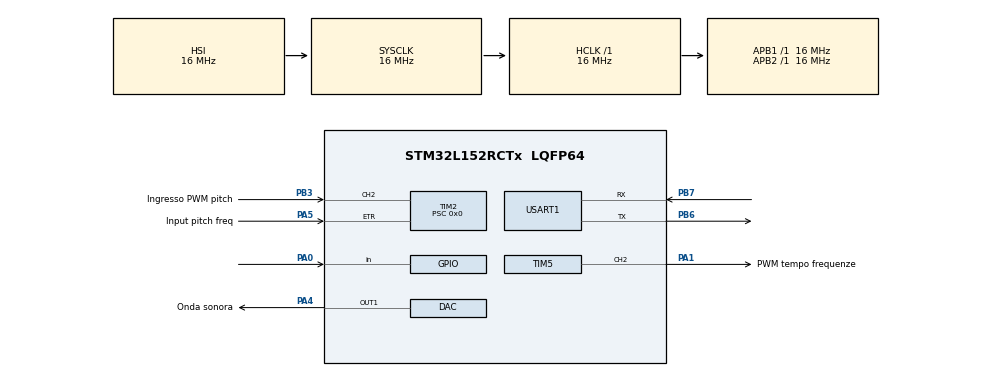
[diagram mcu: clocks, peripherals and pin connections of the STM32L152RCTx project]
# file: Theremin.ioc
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DAC.DAC_Trigger=DAC_TRIGGER_T6_TRGO
Dma.DAC_CH1.0.Direction=DMA_MEMORY_TO_PERIPH
Dma.DAC_CH1.0.Instance=DMA1_Channel2
Dma.DAC_CH1.0.MemDataAlignment=DMA_MDATAALIGN_HALFWORD
Dma.DAC_CH1.0.MemInc=DMA_MINC_ENABLE
Dma.DAC_CH1.0.Mode=DMA_CIRCULAR
Dma.DAC_CH1.0.PeriphDataAlignment=DMA_PDATAALIGN_HALFWORD
Dma.DAC_CH1.0.PeriphInc=DMA_PINC_DISABLE
Dma.DAC_CH1.0.Priority=DMA_PRIORITY_HIGH
Dma.Request0=DAC_CH1
Mcu.Family=STM32L1
Mcu.Name=STM32L152RCTx
Mcu.Package=LQFP64
NVIC.DMA1_Channel2_IRQn=true\:0\:0\:false\:false\:true\:false\:true
NVIC.PriorityGroup=NVIC_PRIORITYGROUP_4
NVIC.TIM2_IRQn=true\:0\:0\:false\:false\:true\:true\:true
NVIC.TIM5_IRQn=true\:0\:0\:false\:false\:true\:true\:true
PA0-WKUP1.Signal=GPIO_Input
PA1.GPIO_Label=PWM tempo frequenze
PA1.Signal=S_TIM5_CH2
PA4.GPIO_Label=Onda sonora
PA4.Signal=COMP_DAC1_group
PA5.GPIO_Label=Input pitch freq
PA5.GPIO_PuPd=GPIO_PULLDOWN
PA5.GPIO_Speed=GPIO_SPEED_FREQ_LOW
PA5.Signal=S_TIM2_CH1_ETR
PB3.GPIO_Label=Ingresso PWM pitch
PB3.Signal=S_TIM2_CH2
PB6.Mode=Asynchronous
PB6.Signal=USART1_TX
PB7.Mode=Asynchronous
PB7.Signal=USART1_RX
ProjectManager.HeapSize=0x200
ProjectManager.StackSize=0x400
ProjectManager.TargetToolchain=STM32CubeIDE
RCC.48MHZClocksFreq_Value=24000000
RCC.AHBFreq_Value=16000000
RCC.APB1Freq_Value=16000000
RCC.APB1TimFreq_Value=16000000
RCC.APB2Freq_Value=16000000
RCC.APB2TimFreq_Value=16000000
RCC.HCLKFreq_Value=16000000
RCC.HSE_VALUE=24000000
RCC.HSI_VALUE=16000000
RCC.LSE_VALUE=32768
RCC.MSI_VALUE=2097000
RCC.SYSCLKFreq_VALUE=16000000
RCC.SYSCLKSource=RCC_SYSCLKSOURCE_HSI
RCC.VCOOutputFreq_Value=48000000
SH.COMP_DAC1_group.0=DAC_OUT1,DAC_OUT1
SH.S_TIM2_CH1_ETR.0=TIM2_ETR,ClockSourceETR_Mode2
SH.S_TIM2_CH2.0=TIM2_CH2,TriggerSource_TI2FP2
SH.S_TIM2_CH2.1=TIM2_CH2,Input_Capture2_from_TI2
SH.S_TIM5_CH2.0=TIM5_CH2,PWM Generation2 CH2
TIM2.Channel-Input_Capture2_from_TI2=TIM_CHANNEL_2
TIM2.Prescaler=0x0
TIM3.Channel-PWM\ Generation2\ No\ Output=TIM_CHANNEL_2
TIM5.AutoReloadPreload=TIM_AUTORELOAD_PRELOAD_ENABLE
TIM5.Channel-PWM\ Generation2\ CH2=TIM_CHANNEL_2
TIM5.Period=160000
TIM5.Pulse-PWM\ Generation2\ CH2=0x1f40
TIM6.Period=624
TIM6.TIM_MasterOutputTrigger=TIM_TRGO_UPDATE
USART1.VirtualMode=VM_ASYNC
VP_TIM2_VS_ControllerModeReset.Mode=Reset Mode
VP_TIM3_VS_no_output2.Mode=PWM Generation2 No Output
VP_TIM5_VS_ClockSourceINT.Mode=Internal
VP_TIM6_VS_ClockSourceINT.Mode=Enable_Timer
board=custom

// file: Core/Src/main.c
/* USER CODE BEGIN Header */
/**
  ******************************************************************************
  * @file           : main.c
  * @brief          : Main program body
  ******************************************************************************
  * @attention
  *
  * <h2><center>&copy; Copyright (c) 2021 STMicroelectronics.
  * All rights reserved.</center></h2>
  *
  * This software component is licensed by ST under BSD 3-Clause license,
  * the "License"; You may not use this file except in compliance with the
  * License. You may obtain a copy of the License at:
  *                        opensource.org/licenses/BSD-3-Clause
  *
  ******************************************************************************
  */
/* USER CODE END Header */
#include "main.h"

DAC_HandleTypeDef hdac;
DMA_HandleTypeDef hdma_dac_ch1;

TIM_HandleTypeDef htim2;
TIM_HandleTypeDef htim3;
TIM_HandleTypeDef htim5;
TIM_HandleTypeDef htim6;

UART_HandleTypeDef huart1;

void SystemClock_Config(void);
static void MX_GPIO_Init(void);
static void MX_DMA_Init(void);
static void MX_DAC_Init(void);
static void MX_TIM6_Init(void);
static void MX_USART1_UART_Init(void);
static void MX_TIM2_Init(void);
static void MX_TIM3_Init(void);
static void MX_TIM5_Init(void);

int main(void)
{
  /* USER CODE BEGIN 1 */
	int sample = 0;
  /* USER CODE END 1 */

  /* MCU Configuration--------------------------------------------------------*/

  /* Reset of all peripherals, Initializes the Flash interface and the Systick. */
  HAL_Init();

  /* Configure the system clock */
  SystemClock_Config();

  /* Initialize all configured peripherals */
  MX_GPIO_Init();
  MX_DMA_Init();
  MX_DAC_Init();
  MX_TIM6_Init();
  MX_USART1_UART_Init();
  MX_TIM2_Init();
  MX_TIM3_Init();
  MX_TIM5_Init();

  /* Infinite loop */
  /* USER CODE BEGIN WHILE */

  dbg_uart_transmit(&huart1, "Theremin!\n", 12);
  bios_out_sample_DMA(&htim6,&hdac);
  pwm_time_wave_start(&htim5);
  pitch_measure_start(&htim2);
  while (1)
  {

	  /*for(int i = 0;i < 32000; i++)
	  	{
	  		a++;
	  	}
	  a = 0;*/
	  //out_sample(&hdac,  (1 + wave_samples[sample])*2000);
	  //out_sample(&hdac,   wave_samples2[sample]);
	  if(sample==179)
	  {
		  sample=0;
	  }
	  else
	  {
		  sample++;
	  }

    /* USER CODE END WHILE */

  }
}

void SystemClock_Config(void)
{
  RCC_OscInitTypeDef RCC_OscInitStruct = {0};
  RCC_ClkInitTypeDef RCC_ClkInitStruct = {0};

  /** Configure the main internal regulator output voltage
  */
  __HAL_PWR_VOLTAGESCALING_CONFIG(PWR_REGULATOR_VOLTAGE_SCALE1);
  /** Initializes the RCC Oscillators according to the specified parameters
  * in the RCC_OscInitTypeDef structure.
  */
  RCC_OscInitStruct.OscillatorType = RCC_OSCILLATORTYPE_HSI;
  RCC_OscInitStruct.HSIState = RCC_HSI_ON;
  RCC_OscInitStruct.HSICalibrationValue = RCC_HSICALIBRATION_DEFAULT;
  RCC_OscInitStruct.PLL.PLLState = RCC_PLL_NONE;
  if (HAL_RCC_OscConfig(&RCC_OscInitStruct) != HAL_OK)
  {
    Error_Handler();
  }
  /** Initializes the CPU, AHB and APB buses clocks
  */
  RCC_ClkInitStruct.ClockType = RCC_CLOCKTYPE_HCLK|RCC_CLOCKTYPE_SYSCLK
                              |RCC_CLOCKTYPE_PCLK1|RCC_CLOCKTYPE_PCLK2;
  RCC_ClkInitStruct.SYSCLKSource = RCC_SYSCLKSOURCE_HSI;
  RCC_ClkInitStruct.AHBCLKDivider = RCC_SYSCLK_DIV1;
  RCC_ClkInitStruct.APB1CLKDivider = RCC_HCLK_DIV1;
  RCC_ClkInitStruct.APB2CLKDivider = RCC_HCLK_DIV1;

  if (HAL_RCC_ClockConfig(&RCC_ClkInitStruct, FLASH_LATENCY_0) != HAL_OK)
  {
    Error_Handler();
  }
}

static void MX_DAC_Init(void)
{

  DAC_ChannelConfTypeDef sConfig = {0};

  /** DAC Initialization
  */
  hdac.Instance = DAC;
  if (HAL_DAC_Init(&hdac) != HAL_OK)
  {
    Error_Handler();
  }
  /** DAC channel OUT1 config
  */
  sConfig.DAC_Trigger = DAC_TRIGGER_T6_TRGO;
  sConfig.DAC_OutputBuffer = DAC_OUTPUTBUFFER_ENABLE;
  if (HAL_DAC_ConfigChannel(&hdac, &sConfig, DAC_CHANNEL_1) != HAL_OK)
  {
    Error_Handler();
  }

}

static void MX_TIM2_Init(void)
{

  TIM_ClockConfigTypeDef sClockSourceConfig = {0};
  TIM_SlaveConfigTypeDef sSlaveConfig = {0};
  TIM_MasterConfigTypeDef sMasterConfig = {0};
  TIM_IC_InitTypeDef sConfigIC = {0};

  htim2.Instance = TIM2;
  htim2.Init.Prescaler = 0x0;
  htim2.Init.CounterMode = TIM_COUNTERMODE_UP;
  htim2.Init.Period = 65535;
  htim2.Init.ClockDivision = TIM_CLOCKDIVISION_DIV1;
  htim2.Init.AutoReloadPreload = TIM_AUTORELOAD_PRELOAD_DISABLE;
  if (HAL_TIM_Base_Init(&htim2) != HAL_OK)
  {
    Error_Handler();
  }
  sClockSourceConfig.ClockSource = TIM_CLOCKSOURCE_ETRMODE2;
  sClockSourceConfig.ClockPolarity = TIM_CLOCKPOLARITY_NONINVERTED;
  sClockSourceConfig.ClockPrescaler = TIM_CLOCKPRESCALER_DIV1;
  sClockSourceConfig.ClockFilter = 0;
  if (HAL_TIM_ConfigClockSource(&htim2, &sClockSourceConfig) != HAL_OK)
  {
    Error_Handler();
  }
  if (HAL_TIM_IC_Init(&htim2) != HAL_OK)
  {
    Error_Handler();
  }
  sSlaveConfig.SlaveMode = TIM_SLAVEMODE_RESET;
  sSlaveConfig.InputTrigger = TIM_TS_TI2FP2;
  sSlaveConfig.TriggerPolarity = TIM_INPUTCHANNELPOLARITY_RISING;
  sSlaveConfig.TriggerFilter = 0;
  if (HAL_TIM_SlaveConfigSynchro(&htim2, &sSlaveConfig) != HAL_OK)
  {
    Error_Handler();
  }
  sMasterConfig.MasterOutputTrigger = TIM_TRGO_RESET;
  sMasterConfig.MasterSlaveMode = TIM_MASTERSLAVEMODE_DISABLE;
  if (HAL_TIMEx_MasterConfigSynchronization(&htim2, &sMasterConfig) != HAL_OK)
  {
    Error_Handler();
  }
  sConfigIC.ICPolarity = TIM_INPUTCHANNELPOLARITY_RISING;
  sConfigIC.ICSelection = TIM_ICSELECTION_DIRECTTI;
  sConfigIC.ICPrescaler = TIM_ICPSC_DIV1;
  sConfigIC.ICFilter = 0;
  if (HAL_TIM_IC_ConfigChannel(&htim2, &sConfigIC, TIM_CHANNEL_2) != HAL_OK)
  {
    Error_Handler();
  }

}

static void MX_TIM3_Init(void)
{

  TIM_MasterConfigTypeDef sMasterConfig = {0};
  TIM_OC_InitTypeDef sConfigOC = {0};

  htim3.Instance = TIM3;
  htim3.Init.Prescaler = 0;
  htim3.Init.CounterMode = TIM_COUNTERMODE_UP;
  htim3.Init.Period = 65535;
  htim3.Init.ClockDivision = TIM_CLOCKDIVISION_DIV1;
  htim3.Init.AutoReloadPreload = TIM_AUTORELOAD_PRELOAD_DISABLE;
  if (HAL_TIM_PWM_Init(&htim3) != HAL_OK)
  {
    Error_Handler();
  }
  sMasterConfig.MasterOutputTrigger = TIM_TRGO_RESET;
  sMasterConfig.MasterSlaveMode = TIM_MASTERSLAVEMODE_DISABLE;
  if (HAL_TIMEx_MasterConfigSynchronization(&htim3, &sMasterConfig) != HAL_OK)
  {
    Error_Handler();
  }
  sConfigOC.OCMode = TIM_OCMODE_PWM1;
  sConfigOC.Pulse = 0;
  sConfigOC.OCPolarity = TIM_OCPOLARITY_HIGH;
  sConfigOC.OCFastMode = TIM_OCFAST_DISABLE;
  if (HAL_TIM_PWM_ConfigChannel(&htim3, &sConfigOC, TIM_CHANNEL_2) != HAL_OK)
  {
    Error_Handler();
  }

}

static void MX_TIM5_Init(void)
{

  TIM_ClockConfigTypeDef sClockSourceConfig = {0};
  TIM_MasterConfigTypeDef sMasterConfig = {0};
  TIM_OC_InitTypeDef sConfigOC = {0};

  htim5.Instance = TIM5;
  htim5.Init.Prescaler = 0;
  htim5.Init.CounterMode = TIM_COUNTERMODE_UP;
  htim5.Init.Period = 160000;
  htim5.Init.ClockDivision = TIM_CLOCKDIVISION_DIV1;
  htim5.Init.AutoReloadPreload = TIM_AUTORELOAD_PRELOAD_ENABLE;
  if (HAL_TIM_Base_Init(&htim5) != HAL_OK)
  {
    Error_Handler();
  }
  sClockSourceConfig.ClockSource = TIM_CLOCKSOURCE_INTERNAL;
  if (HAL_TIM_ConfigClockSource(&htim5, &sClockSourceConfig) != HAL_OK)
  {
    Error_Handler();
  }
  if (HAL_TIM_PWM_Init(&htim5) != HAL_OK)
  {
    Error_Handler();
  }
  sMasterConfig.MasterOutputTrigger = TIM_TRGO_RESET;
  sMasterConfig.MasterSlaveMode = TIM_MASTERSLAVEMODE_DISABLE;
  if (HAL_TIMEx_MasterConfigSynchronization(&htim5, &sMasterConfig) != HAL_OK)
  {
    Error_Handler();
  }
  sConfigOC.OCMode = TIM_OCMODE_PWM1;
  sConfigOC.Pulse = 0x1f40;
  sConfigOC.OCPolarity = TIM_OCPOLARITY_HIGH;
  sConfigOC.OCFastMode = TIM_OCFAST_DISABLE;
  if (HAL_TIM_PWM_ConfigChannel(&htim5, &sConfigOC, TIM_CHANNEL_2) != HAL_OK)
  {
    Error_Handler();
  }
  HAL_TIM_MspPostInit(&htim5);

}

static void MX_TIM6_Init(void)
{

  TIM_MasterConfigTypeDef sMasterConfig = {0};

  htim6.Instance = TIM6;
  htim6.Init.Prescaler = 0;
  htim6.Init.CounterMode = TIM_COUNTERMODE_UP;
  htim6.Init.Period = 624;
  htim6.Init.AutoReloadPreload = TIM_AUTORELOAD_PRELOAD_DISABLE;
  if (HAL_TIM_Base_Init(&htim6) != HAL_OK)
  {
    Error_Handler();
  }
  sMasterConfig.MasterOutputTrigger = TIM_TRGO_UPDATE;
  sMasterConfig.MasterSlaveMode = TIM_MASTERSLAVEMODE_DISABLE;
  if (HAL_TIMEx_MasterConfigSynchronization(&htim6, &sMasterConfig) != HAL_OK)
  {
    Error_Handler();
  }

}

static void MX_USART1_UART_Init(void)
{

  huart1.Instance = USART1;
  huart1.Init.BaudRate = 115200;
  huart1.Init.WordLength = UART_WORDLENGTH_8B;
  huart1.Init.StopBits = UART_STOPBITS_1;
  huart1.Init.Parity = UART_PARITY_NONE;
  huart1.Init.Mode = UART_MODE_TX_RX;
  huart1.Init.HwFlowCtl = UART_HWCONTROL_NONE;
  huart1.Init.OverSampling = UART_OVERSAMPLING_16;
  if (HAL_UART_Init(&huart1) != HAL_OK)
  {
    Error_Handler();
  }

}

static void MX_DMA_Init(void)
{

  /* DMA controller clock enable */
  __HAL_RCC_DMA1_CLK_ENABLE();

  /* DMA interrupt init */
  /* DMA1_Channel2_IRQn interrupt configuration */
  HAL_NVIC_SetPriority(DMA1_Channel2_IRQn, 0, 0);
  HAL_NVIC_EnableIRQ(DMA1_Channel2_IRQn);

}

static void MX_GPIO_Init(void)
{
  GPIO_InitTypeDef GPIO_InitStruct = {0};

  /* GPIO Ports Clock Enable */
  __HAL_RCC_GPIOA_CLK_ENABLE();
  __HAL_RCC_GPIOB_CLK_ENABLE();

  /*Configure GPIO pin : PA0 */
  GPIO_InitStruct.Pin = GPIO_PIN_0;
  GPIO_InitStruct.Mode = GPIO_MODE_INPUT;
  GPIO_InitStruct.Pull = GPIO_NOPULL;
  HAL_GPIO_Init(GPIOA, &GPIO_InitStruct);

}

void Error_Handler(void)
{
  __disable_irq();
  while (1)
  {
  }
}

/************************ (C) COPYRIGHT STMicroelectronics *****END OF FILE****/
